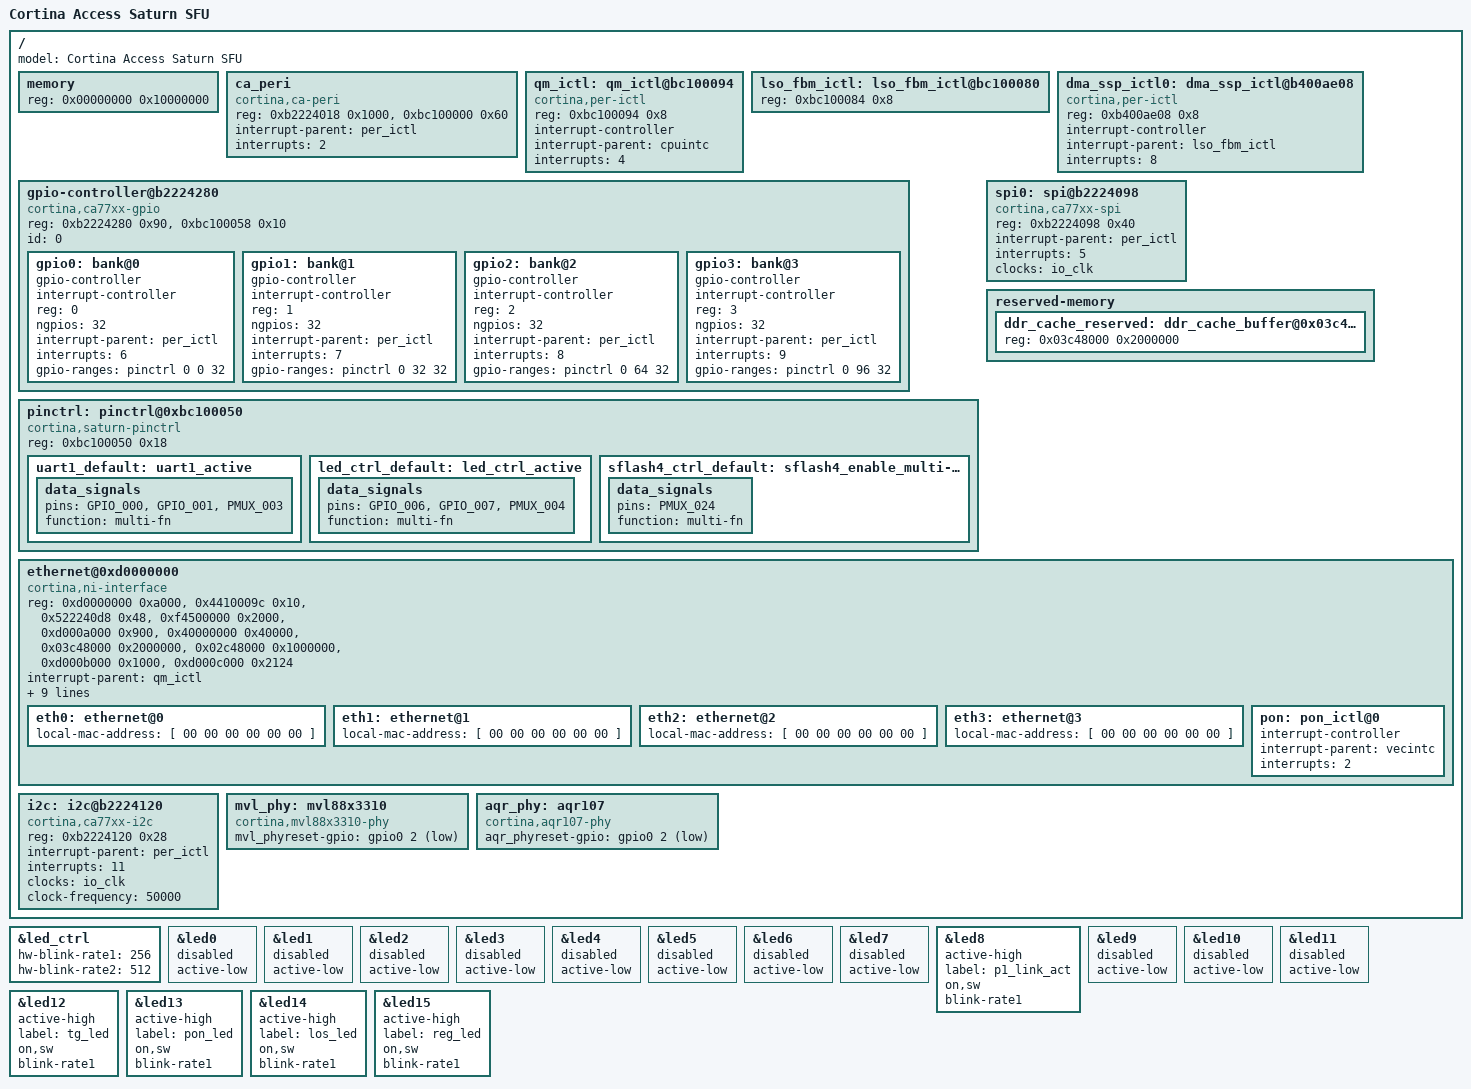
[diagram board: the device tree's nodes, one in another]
/*
 * dts file for Cortina Access Saturn Development Board
 *
 * Copyright (C) 2016, Cortina Access
 */

/dts-v1/;
#include <dt-bindings/gpio/gpio.h>
#include <dt-bindings/reset/cortina,rst-mgr.h>
#include "saturn_soc.dtsi"
#include "saturn_spinand.dtsi"
#include "saturn_sflash.dtsi"
#include "saturn_led.dtsi"

/* board specific and SoC overrides below */
/ {
	model = "Cortina Access Saturn SFU";
	#address-cells = <1>;
	#size-cells = <1>;

	memory { /* 256MB */
		device_type = "memory";
		reg = <0x00000000 0x10000000>;
	};

	ca_peri{
		compatible = "cortina,ca-peri";
		reg = <0xb2224018 0x1000>,
		      <0xbc100000 0x60>;
		interrupt-parent = <&per_ictl>;
		interrupts = <2>;
		interrupt-names = "TMR1";
	};

	qm_ictl: qm_ictl@bc100094 {     /* QM interrupt */
		compatible = "cortina,per-ictl";
		reg = <0xbc100094  0x8>;
		interrupt-controller;
		#interrupt-cells = <1>;
		interrupt-parent = <&cpuintc>;
		interrupts = <4>;
	};

	lso_fbm_ictl: lso_fbm_ictl@bc100080 {	/* LSO_FBM interrupt */
		reg = <0xbc100084  0x8>;
	};

	dma_ssp_ictl0: dma_ssp_ictl@b400ae08 {     /* DMA_SSP0 interrupt */
		compatible = "cortina,per-ictl";
		reg = <0xb400ae08  0x8>;
		interrupt-controller;
		#interrupt-cells = <1>;
		interrupt-parent = <&lso_fbm_ictl>;
		interrupts = <8>;
	};

	gpio-controller@b2224280 {
		#address-cells = <1>;
		#size-cells = <0>;
		compatible = "cortina,ca77xx-gpio";
		reg = <0xb2224280 0x90>,
		      <0xbc100058 0x10>;
		id = <0>;

		/* bank 0 with an interrupt */
		gpio0: bank@0 {
			gpio-controller;
			interrupt-controller;
			reg = <0>;
			ngpios = <32>;
			#gpio-cells = <2>;
			#interrupt-cells = <2>;
			interrupt-parent = <&per_ictl>;
			interrupts = <6>;
			gpio-ranges = <&pinctrl 0 0 32>;
		};

		/* bank 1 with an interrupt */
		gpio1: bank@1 {
			gpio-controller;
			interrupt-controller;
			reg = <1>;
			ngpios = <32>;
			#gpio-cells = <2>;
			#interrupt-cells = <2>;
			interrupt-parent = <&per_ictl>;
			interrupts = <7>;
			gpio-ranges = <&pinctrl 0 32 32>;
		};

		/* bank 2 without interrupt */
		gpio2: bank@2 {
			gpio-controller;
			interrupt-controller;
			reg = <2>;
			ngpios = <32>;
			#gpio-cells = <2>;
			#interrupt-cells = <2>;
			interrupt-parent = <&per_ictl>;
			interrupts = <8>;
			gpio-ranges = <&pinctrl 0 64 32>;
		};

		/* bank 3 without interrupt */
		gpio3: bank@3 {
			gpio-controller;
			interrupt-controller;
			reg = <3>;
			ngpios = <32>;
			#gpio-cells = <2>;
			#interrupt-cells = <2>;
			interrupt-parent = <&per_ictl>;
			interrupts = <9>;
			gpio-ranges = <&pinctrl 0 96 32>;
		};
	};

	pinctrl: pinctrl@0xbc100050 {
		compatible = "cortina,saturn-pinctrl";
		reg = <0xbc100050 0x18>;

		uart1_default: uart1_active {
			data_signals {
				pins = "GPIO_000", "GPIO_001", "PMUX_003";
				function = "multi-fn";
			};
		};

		led_ctrl_default: led_ctrl_active {
			data_signals {
				pins = "GPIO_006", "GPIO_007", "PMUX_004";
				function = "multi-fn";
			};
		};

		sflash4_ctrl_default: sflash4_enable_multi-io {
			data_signals {
				pins = "PMUX_024";
				function = "multi-fn";
			};
		};
	};


	spi0: spi@b2224098 {
		compatible = "cortina,ca77xx-spi";
		reg = <0xb2224098 0x40>;
		interrupt-parent = <&per_ictl>;
		interrupts = <5>;
		clocks = <&io_clk>;
		#address-cells = <1>;
		#size-cells = <0>;
	};


       /* Reserver memory region for Hash/FBM/NE and etc.
         * Fixme when NE team finalize size and offset
         */
        reserved-memory {
		#address-cells = <1>;
		#size-cells = <1>;
          ranges;
		ddr_cache_reserved: ddr_cache_buffer@0x03c48000 {
                           reg = <0x03c48000 0x2000000>;    /* reserved memory area in DDR $-coherent */
               };
        };


        ethernet@0xd0000000 {
                compatible = "cortina,ni-interface";

                reg = <0xd0000000 0xa000>,       /* reserved memory area for HV NE(APB0) module registers */
                      <0x4410009c 0x10>,         /* reserved memory area for Global Network Engine Interrupt registers */
                      <0x522240d8 0x48>,         /* reserved memory area for MDIO registers */
                      <0xf4500000 0x2000>,       /* reserved memory area for XRAM */
                      <0xd000a000 0x900>,        /* reserved memory area for DMA LSO */
                      <0x40000000 0x40000>,      /* reserved memory area in SRAM */
                      <0x03c48000 0x2000000>,    /* reserved memory area in DDR $-coherent */
                      <0x02c48000 0x1000000>,    /* reserved memory area in DDR non-$cable, no used in Saturn SFU */
		      <0xd000b000 0x1000>,       /* reserved memory area for internal RTL8211 PHY registers */
                      <0xd000c000 0x2124>;       /* reserved memory area for XFI registers */

                interrupt-parent=<&qm_ictl>;
                interrupts=<8>, <9>, <10>, <11>, <12>, <13>, <14>, <15>, <16>, <17>;

                resets = <&block_rst NI_RESET>, <&block_rst L2FE_RESET>, <&block_rst L2TM_RESET>, <&block_rst L3FE_RESET>, <&block_rst SDRAM_RESET>, <&block_rst TQM_RESET>, <&block_rst DMA_RESET>, <&block_rst FBM_RESET>, <&global_cfg EXT_RESET>;
                reset-names = "ni_reset", "l2fe_reset", "l2tm_reset", "l3fe_reset", "sdram_reset", "tqm_reset", "dma_reset", "fbm_reset", "ext_reset";
               memory-region = <&ddr_cache_reserved>;

		dyinggasp-gpio = <&gpio0 1 GPIO_ACTIVE_LOW>;

		eth0: ethernet@0 {
			local-mac-address = [ 00 00 00 00 00 00 ];
		};

		eth1: ethernet@1 {
			local-mac-address = [ 00 00 00 00 00 00 ];
		};

		eth2: ethernet@2 {
			local-mac-address = [ 00 00 00 00 00 00 ];
		};

		eth3: ethernet@3 {
			local-mac-address = [ 00 00 00 00 00 00 ];
		};
        pon: pon_ictl@0 {
                interrupt-controller;
                #interrupt-cells = <1>;
                interrupt-parent = <&vecintc>;
                interrupts = <2>;
        };
        };


         i2c: i2c@b2224120  {
                  compatible = "cortina,ca77xx-i2c";
                  reg = <0xb2224120 0x28>;
                  interrupt-parent = <&per_ictl>;
                  interrupts = <11>;
                  device_type = "i2c";
                  clocks = <&io_clk>;
                  clock-frequency = <50000>;
         };


	mvl_phy: mvl88x3310 { /* MVL 10G phy Devicetree Node */
		compatible = "cortina,mvl88x3310-phy";
		mvl_phyreset-gpio = <&gpio0 2 GPIO_ACTIVE_LOW>;
		status = "okay";
	};

	aqr_phy: aqr107 { /* AQR 10G phy Devicetree Node */
		compatible = "cortina,aqr107-phy";
		aqr_phyreset-gpio = <&gpio0 2 GPIO_ACTIVE_LOW>;
		status = "okay";
	};


};

&led_ctrl {
	hw-blink-rate1 = <256>;
	hw-blink-rate2 = <512>;
};

&led0 {
	active-low;
	status = "disabled";
};

&led1 {
	active-low;
	status = "disabled";
};

&led2 {
	active-low;
	status = "disabled";
};

&led3 {
	active-low;
	status = "disabled";
};

&led4 {
	active-low;
	status = "disabled";
};

&led5 {
	active-low;
	status = "disabled";
};

&led6 {
	active-low;
	status = "disabled";
};

&led7 {
	active-low;
	status = "disabled";
};

&led8 {
	active-high;
	label = "p1_link_act";
	on,sw;
	blink-rate1;
};

&led9 {
	active-low;
	status = "disabled";
};

&led10 {
	active-low;
	status = "disabled";
};

&led11 {
	active-low;
	status = "disabled";
};

&led12 {
	active-high;
	label = "tg_led";
	on,sw;
	blink-rate1;
};

&led13 {
	active-high;
	label = "pon_led";
	on,sw;
	blink-rate1;
};

&led14 {
	active-high;
	label = "los_led";
	on,sw;
	blink-rate1;
};

&led15 {
	active-high;
	label = "reg_led";
	on,sw;
	blink-rate1;
};


